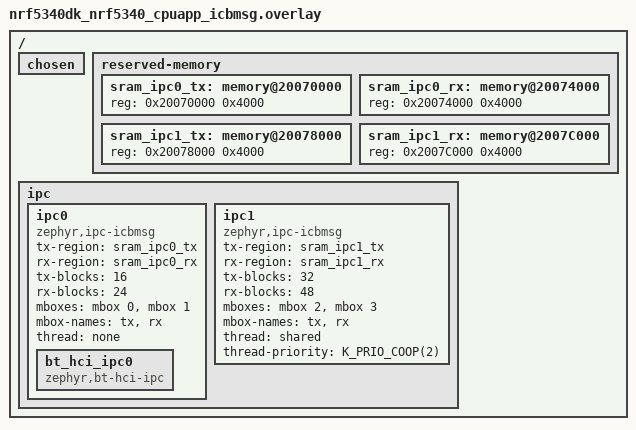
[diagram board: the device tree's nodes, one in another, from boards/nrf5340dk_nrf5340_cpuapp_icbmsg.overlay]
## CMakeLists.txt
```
#
# Copyright (c) 2022 Nordic Semiconductor ASA
#
# SPDX-License-Identifier: Apache-2.0
#

cmake_minimum_required(VERSION 3.20.0)

set(REMOTE_ZEPHYR_DIR ${CMAKE_CURRENT_BINARY_DIR}/ipc_service_remote-prefix/src/ipc_service_remote-build/zephyr)

if("${BOARD}" STREQUAL "nrf5340dk_nrf5340_cpuapp")
  set(BOARD_REMOTE "nrf5340dk_nrf5340_cpunet")
else()
  message(FATAL_ERROR "${BOARD} is not supported for this sample")
endif()

find_package(Zephyr REQUIRED HINTS $ENV{ZEPHYR_BASE})
project(ipc_service)

target_sources(app PRIVATE src/main.c)

include(ExternalProject)

ExternalProject_Add(
  ipc_service_remote
  SOURCE_DIR ${APPLICATION_SOURCE_DIR}/remote
  INSTALL_COMMAND ""      # This particular build system has no install command
  CMAKE_CACHE_ARGS -DBOARD:STRING=${BOARD_REMOTE} -DDTC_OVERLAY_FILE:STRING=${DTC_OVERLAY_FILE_REMOTE}
  BUILD_BYPRODUCTS "${REMOTE_ZEPHYR_DIR}/${KERNEL_BIN_NAME}"
  # NB: Do we need to pass on more CMake variables?
  BUILD_ALWAYS True
)
```

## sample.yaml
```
sample:
  name: IPC Service example integration (icmsg multi endpoint backend)
tests:
  sample.ipc.multi_endpoint:
    platform_allow: nrf5340dk_nrf5340_cpuapp
    integration_platforms:
      - nrf5340dk_nrf5340_cpuapp
    tags: ipc
    harness: remote
```

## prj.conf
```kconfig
CONFIG_PRINTK=y
CONFIG_LOG_PRINTK=n

CONFIG_IPC_SERVICE=y
CONFIG_IPC_SERVICE_BACKEND_ICMSG_ME_NOCOPY_RX=y
CONFIG_MBOX=y

CONFIG_LOG=y
CONFIG_IPC_SERVICE_LOG_LEVEL_INF=y
```

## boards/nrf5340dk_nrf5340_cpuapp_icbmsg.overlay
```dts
/*
 * Copyright (c) 2023 Nordic Semiconductor ASA
 *
 * SPDX-License-Identifier: Apache-2.0
 */

/ {
	chosen {
		/delete-property/ zephyr,ipc_shm;
	};

	reserved-memory {
		/delete-node/ memory@20070000;

		sram_ipc0_tx: memory@20070000 {
			reg = <0x20070000 0x4000>;
		};

		sram_ipc0_rx: memory@20074000 {
			reg = <0x20074000 0x4000>;
		};

		sram_ipc1_tx: memory@20078000 {
			reg = <0x20078000 0x4000>;
		};

		sram_ipc1_rx: memory@2007C000 {
			reg = <0x2007C000 0x4000>;
		};
	};

	ipc {
		/delete-node/ ipc0;

		ipc0: ipc0 {
			compatible = "zephyr,ipc-icbmsg";
			tx-region = <&sram_ipc0_tx>;
			rx-region = <&sram_ipc0_rx>;
			tx-blocks = <16>;
			rx-blocks = <24>;
			mboxes = <&mbox 0>, <&mbox 1>;
			mbox-names = "tx", "rx";
			status = "okay";
			thread = "none";

			bt_hci_ipc0: bt_hci_ipc0 {
				compatible = "zephyr,bt-hci-ipc";
				status = "okay";
			};
		};

		ipc1: ipc1 {
			compatible = "zephyr,ipc-icbmsg";
			tx-region = <&sram_ipc1_tx>;
			rx-region = <&sram_ipc1_rx>;
			tx-blocks = <32>;
			rx-blocks = <48>;
			mboxes = <&mbox 2>, <&mbox 3>;
			mbox-names = "tx", "rx";
			status = "okay";
			thread = "shared";
			thread-priority = "K_PRIO_COOP(2)";
		};
	};
};
```

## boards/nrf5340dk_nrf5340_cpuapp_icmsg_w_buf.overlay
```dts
/*
 * Copyright (c) 2023 Nordic Semiconductor ASA
 *
 * SPDX-License-Identifier: Apache-2.0
 */

/ {
	chosen {
		/delete-property/ zephyr,ipc_shm;
	};

	reserved-memory {
		/delete-node/ memory@20070000;

		sram_ipc0_tx: memory@20070000 {
			reg = <0x20070000 0x4000>;
		};

		sram_ipc0_rx: memory@20074000 {
			reg = <0x20074000 0x4000>;
		};

		sram_ipc1_tx: memory@20078000 {
			reg = <0x20078000 0x4000>;
		};

		sram_ipc1_rx: memory@2007C000 {
			reg = <0x2007C000 0x4000>;
		};
	};

	ipc {
		/delete-node/ ipc0;

		ipc0: ipc0 {
			compatible = "zephyr,ipc-icmsg-with-buf";
			tx-region = <&sram_ipc0_tx>;
			rx-region = <&sram_ipc0_rx>;
			tx-blocks = <16>;
			rx-blocks = <24>;
			mboxes = <&mbox 0>, <&mbox 1>;
			mbox-names = "tx", "rx";
			status = "okay";
		};

		ipc1: ipc1 {
			compatible = "zephyr,ipc-icmsg-with-buf";
			tx-region = <&sram_ipc1_tx>;
			rx-region = <&sram_ipc1_rx>;
			tx-blocks = <32>;
			rx-blocks = <48>;
			mboxes = <&mbox 2>, <&mbox 3>;
			mbox-names = "tx", "rx";
			status = "okay";
		};
	};
};
```

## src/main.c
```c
/*
 * Copyright (c) 2022 Nordic Semiconductor ASA
 *
 * SPDX-License-Identifier: Apache-2.0
 */

#include <zephyr/kernel.h>
#include <zephyr/device.h>

#include <zephyr/ipc/ipc_service.h>

#define STACKSIZE	(4096)
#define PRIORITY	K_PRIO_PREEMPT(2)

K_THREAD_STACK_DEFINE(ipc0A_stack, STACKSIZE);
K_THREAD_STACK_DEFINE(ipc0B_stack, STACKSIZE);
K_THREAD_STACK_DEFINE(ipc1_stack, STACKSIZE);

static volatile uint8_t ipc0A_received_data;
static volatile uint8_t ipc0B_received_data;
static const void *ipc1_received_data;

static K_SEM_DEFINE(ipc0A_bound_sem, 0, 1);
static K_SEM_DEFINE(ipc0B_bound_sem, 0, 1);
static K_SEM_DEFINE(ipc1_bound_sem, 0, 1);

static K_SEM_DEFINE(ipc0A_data_sem, 0, 1);
static K_SEM_DEFINE(ipc0B_data_sem, 0, 1);
static K_SEM_DEFINE(ipc1_data_sem, 0, 1);

/*
 * ==> THREAD 0A (IPC instance 0 - endpoint A) <==
 */

static void ipc0A_ept_bound(void *priv)
{
	k_sem_give(&ipc0A_bound_sem);
}

static void ipc0A_ept_recv(const void *data, size_t len, void *priv)
{
	ipc0A_received_data = *((uint8_t *) data);

	k_sem_give(&ipc0A_data_sem);
}

static struct ipc_ept_cfg ipc0A_ept_cfg = {
	.name = "ipc0A",
	.cb = {
		.bound    = ipc0A_ept_bound,
		.received = ipc0A_ept_recv,
	},
};

static void ipc0A_entry(void *dummy0, void *dummy1, void *dummy2)
{
	ARG_UNUSED(dummy0);
	ARG_UNUSED(dummy1);
	ARG_UNUSED(dummy2);

	const struct device *ipc0_instance;
	unsigned char message = 0;
	struct ipc_ept ipc0A_ept;
	int ret;

	printk("IPC-service HOST [INST 0 - ENDP A] demo started\n");

	ipc0_instance = DEVICE_DT_GET(DT_NODELABEL(ipc0));

	ret = ipc_service_open_instance(ipc0_instance);
	if (ret < 0 && ret != -EALREADY) {
		printk("ipc_service_open_instance() failure\n");
		return;
	}

	/*
	 * Wait 1 sec to give the opportunity to the SECONDARY core to register
	 * the endpoint first
	 */

	k_sleep(K_MSEC(1000));

	ret = ipc_service_register_endpoint(ipc0_instance, &ipc0A_ept, &ipc0A_ept_cfg);
	if (ret < 0) {
		printf("ipc_service_register_endpoint() failure\n");
		return;
	}

	k_sem_take(&ipc0A_bound_sem, K_FOREVER);

	while (message < 100) {
		ret = ipc_service_send(&ipc0A_ept, &message, sizeof(message));
		if (ret < 0) {
			printk("send_message(%d) failed with ret %d\n", message, ret);
			break;
		}

		k_sem_take(&ipc0A_data_sem, K_FOREVER);
		message = ipc0A_received_data;

		printk("HOST [0A]: %d\n", message);
		message++;
	}

	printk("IPC-service HOST [INST 0 - ENDP A] demo ended.\n");
}
K_THREAD_DEFINE(ipc0A_thread_id, STACKSIZE, ipc0A_entry, NULL, NULL, NULL, PRIORITY, 0, 0);

/*
 * ==> THREAD 0B (IPC instance 0 - endpoint B) <==
 */

static void ipc0B_ept_bound(void *priv)
{
	k_sem_give(&ipc0B_bound_sem);
}

static void ipc0B_ept_recv(const void *data, size_t len, void *priv)
{
	ipc0B_received_data = *((uint8_t *) data);

	k_sem_give(&ipc0B_data_sem);
}

static struct ipc_ept_cfg ipc0B_ept_cfg = {
	.name = "ipc0B",
	.cb = {
		.bound    = ipc0B_ept_bound,
		.received = ipc0B_ept_recv,
	},
};

static void ipc0B_entry(void *dummy0, void *dummy1, void *dummy2)
{
	ARG_UNUSED(dummy0);
	ARG_UNUSED(dummy1);
	ARG_UNUSED(dummy2);

	const struct device *ipc0_instance;
	unsigned char message = 0;
	struct ipc_ept ipc0B_ept;
	int ret;

	printk("IPC-service HOST [INST 0 - ENDP B] demo started\n");

	ipc0_instance = DEVICE_DT_GET(DT_NODELABEL(ipc0));

	ret = ipc_service_open_instance(ipc0_instance);
	if (ret < 0 && ret != -EALREADY) {
		printk("ipc_service_open_instance() failure\n");
		return;
	}

	ret = ipc_service_register_endpoint(ipc0_instance, &ipc0B_ept, &ipc0B_ept_cfg);
	if (ret < 0) {
		printf("ipc_service_register_endpoint() failure\n");
		return;
	}

	k_sem_take(&ipc0B_bound_sem, K_FOREVER);

	while (message < 100) {
		ret = ipc_service_send(&ipc0B_ept, &message, sizeof(message));
		if (ret < 0) {
			printk("send_message(%d) failed with ret %d\n", message, ret);
			break;
		}

		k_sem_take(&ipc0B_data_sem, K_FOREVER);
		message = ipc0B_received_data;

		printk("HOST [0B]: %d\n", message);
		message++;
	}

	printk("IPC-service HOST [INST 0 - ENDP B] demo ended.\n");
}
K_THREAD_DEFINE(ipc0B_thread_id, STACKSIZE, ipc0B_entry, NULL, NULL, NULL, PRIORITY, 0, 0);

/*
 * ==> THREAD 1 (IPC instance 1) <==
 *
 * NOTE: This instance is using the NOCOPY copability of the backend.
 */

static struct ipc_ept ipc1_ept;

static void ipc1_ept_bound(void *priv)
{
	k_sem_give(&ipc1_bound_sem);
}

static void ipc1_ept_recv(const void *data, size_t len, void *priv)
{
	ipc_service_hold_rx_buffer(&ipc1_ept, (void *)data);
	ipc1_received_data = data;

	k_sem_give(&ipc1_data_sem);
}

static struct ipc_ept_cfg ipc1_ept_cfg = {
	.name = "ipc1",
	.cb = {
		.bound    = ipc1_ept_bound,
		.received = ipc1_ept_recv,
	},
};

static void ipc1_entry(void *dummy0, void *dummy1, void *dummy2)
{
	ARG_UNUSED(dummy0);
	ARG_UNUSED(dummy1);
	ARG_UNUSED(dummy2);

	const struct device *ipc1_instance;
	unsigned char message = 0;
	int ret;

	printk("IPC-service HOST [INST 1] demo started\n");

	ipc1_instance = DEVICE_DT_GET(DT_NODELABEL(ipc1));

	ret = ipc_service_open_instance(ipc1_instance);
	if (ret < 0 && ret != -EALREADY) {
		printk("ipc_service_open_instance() failure\n");
		return;
	}

	ret = ipc_service_register_endpoint(ipc1_instance, &ipc1_ept, &ipc1_ept_cfg);
	if (ret < 0) {
		printf("ipc_service_register_endpoint() failure\n");
		return;
	}

	k_sem_take(&ipc1_bound_sem, K_FOREVER);

	/*
	 * Wait 1 sec to start sending simultaneously with other threads
	 * the endpoint first
	 */

	k_sleep(K_MSEC(1000));

	while (message < 100) {
		void *tx_buffer;
		uint32_t tx_buffer_size = sizeof(message);

		ret = ipc_service_get_tx_buffer(&ipc1_ept, &tx_buffer, &tx_buffer_size, K_NO_WAIT);
		if (ret < 0) {
			printk("get_tx_buffer(%u) failed with ret %d\n", sizeof(message), ret);
			break;
		}
		if (tx_buffer_size < sizeof(message)) {
			printk("get_tx_buffer modified buffer size to unexpected value %u\n",
					tx_buffer_size);
			break;
		}

		*((uint8_t *) tx_buffer) = message;

		ret = ipc_service_send_nocopy(&ipc1_ept, tx_buffer, sizeof(message));
		if (ret < 0) {
			printk("send_message_nocopy(%u) failed with ret %d\n", message, ret);
			break;
		}

		k_sem_take(&ipc1_data_sem, K_FOREVER);
		message = *((uint8_t *) ipc1_received_data);

		ret = ipc_service_release_rx_buffer(&ipc1_ept, (void *) ipc1_received_data);
		if (ret < 0) {
			printk("release_rx_buffer() failed with ret %d\n", ret);
			break;
		}

		printk("HOST [1]: %d\n", message);
		message++;
	}

	printk("IPC-service HOST [INST 1] demo ended.\n");
}
K_THREAD_DEFINE(ipc1_thread_id, STACKSIZE, ipc1_entry, NULL, NULL, NULL, PRIORITY, 0, 0);
```
